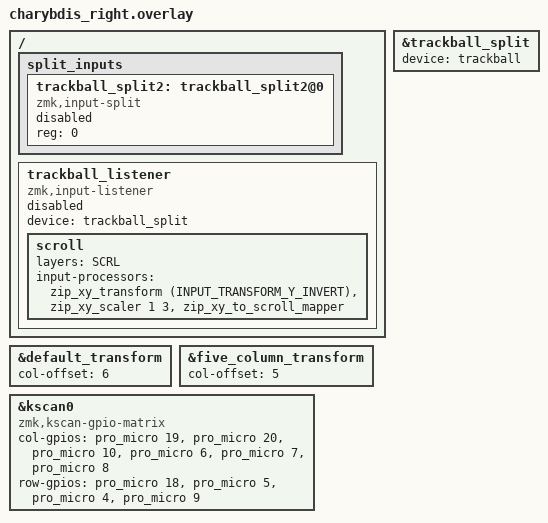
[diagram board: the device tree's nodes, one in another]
#include "charybdis.dtsi"
#include "charybdis_3610.dtsi"
#include <dt-bindings/zmk/input_transform.h>
#include <input/processors.dtsi>

&default_transform {
	col-offset = <6>;
};

&five_column_transform {
	col-offset = <5>;
};

&kscan0 {
	compatible = "zmk,kscan-gpio-matrix";
	
	col-gpios
		= <&pro_micro 19 (GPIO_ACTIVE_HIGH | GPIO_PULL_DOWN)>
		, <&pro_micro 20 (GPIO_ACTIVE_HIGH | GPIO_PULL_DOWN)>
		, <&pro_micro 10 (GPIO_ACTIVE_HIGH | GPIO_PULL_DOWN)>
		, <&pro_micro 6 (GPIO_ACTIVE_HIGH | GPIO_PULL_DOWN)>
		, <&pro_micro 7 (GPIO_ACTIVE_HIGH | GPIO_PULL_DOWN)>
		, <&pro_micro 8 (GPIO_ACTIVE_HIGH | GPIO_PULL_DOWN)>
		;

	row-gpios
		= <&pro_micro 18 GPIO_ACTIVE_HIGH>
		, <&pro_micro 5 GPIO_ACTIVE_HIGH>
		, <&pro_micro 4 GPIO_ACTIVE_HIGH>
		, <&pro_micro 9 GPIO_ACTIVE_HIGH>
		;
};

&trackball_split { 
	device = <&trackball>; 
	};
&trackball_split2 { 
	status = "disabled"; 
};

#define WIN 1
#define SYMBOLS 2
#define NUMBERS 3
#define NAV 4
#define FUNCTION 5
#define BLUETOOTH 6
#define MOUSE 7
#define CLICK 8
#define SCRL 9
#define BIRO 10

/ {
  split_inputs {
    #address-cells = <1>;
    #size-cells = <0>;

    trackball_split2: trackball_split2@0 {
      compatible = "zmk,input-split";
      reg = <0>;
    };
  };

  trackball_listener: trackball_listener {
    compatible = "zmk,input-listener";
    status = "disabled";
    device = <&trackball_split>;

    scroll {
      layers = <SCRL>;
      input-processors = <&zip_xy_transform (INPUT_TRANSFORM_Y_INVERT)>, <&zip_xy_scaler 1 3>, <&zip_xy_to_scroll_mapper>;
    };

  };
};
